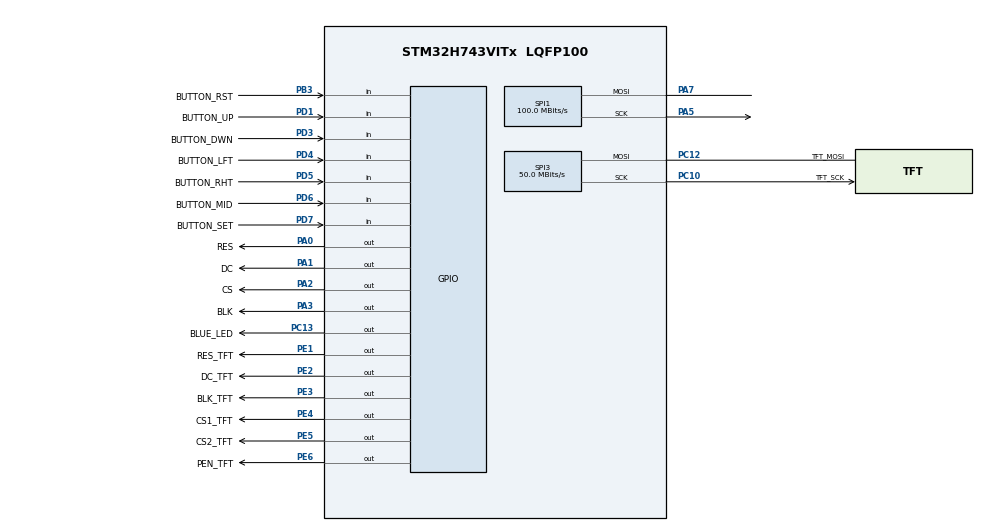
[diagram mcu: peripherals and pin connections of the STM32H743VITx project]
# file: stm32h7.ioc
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CORTEX_M7.CPU_DCache=Disabled
CORTEX_M7.CPU_ICache=Disabled
CORTEX_M7.Enable_S-Cortex_Memory_Protection_Unit_Region11_Settings_S=__NULL
CORTEX_M7.Enable_S-Cortex_Memory_Protection_Unit_Region1_Settings_S=__NULL
CORTEX_M7.default_mode_Activation=0
Dma.Request0=SPI1_TX
Dma.Request1=SPI3_TX
Dma.SPI1_TX.0.Direction=DMA_MEMORY_TO_PERIPH
Dma.SPI1_TX.0.EventEnable=DISABLE
Dma.SPI1_TX.0.FIFOMode=DMA_FIFOMODE_DISABLE
Dma.SPI1_TX.0.Instance=DMA1_Stream0
Dma.SPI1_TX.0.MemDataAlignment=DMA_MDATAALIGN_BYTE
Dma.SPI1_TX.0.MemInc=DMA_MINC_ENABLE
Dma.SPI1_TX.0.Mode=DMA_NORMAL
Dma.SPI1_TX.0.PeriphDataAlignment=DMA_PDATAALIGN_BYTE
Dma.SPI1_TX.0.PeriphInc=DMA_PINC_DISABLE
Dma.SPI1_TX.0.Polarity=HAL_DMAMUX_REQ_GEN_RISING
Dma.SPI1_TX.0.Priority=DMA_PRIORITY_HIGH
Dma.SPI1_TX.0.RequestNumber=1
Dma.SPI1_TX.0.SignalID=NONE
Dma.SPI1_TX.0.SyncEnable=DISABLE
Dma.SPI1_TX.0.SyncPolarity=HAL_DMAMUX_SYNC_NO_EVENT
Dma.SPI1_TX.0.SyncRequestNumber=1
Dma.SPI1_TX.0.SyncSignalID=NONE
Dma.SPI3_TX.1.Direction=DMA_MEMORY_TO_PERIPH
Dma.SPI3_TX.1.EventEnable=DISABLE
Dma.SPI3_TX.1.FIFOMode=DMA_FIFOMODE_ENABLE
Dma.SPI3_TX.1.FIFOThreshold=DMA_FIFO_THRESHOLD_FULL
Dma.SPI3_TX.1.Instance=DMA1_Stream2
Dma.SPI3_TX.1.MemBurst=DMA_MBURST_SINGLE
Dma.SPI3_TX.1.MemDataAlignment=DMA_MDATAALIGN_BYTE
Dma.SPI3_TX.1.MemInc=DMA_MINC_ENABLE
Dma.SPI3_TX.1.Mode=DMA_NORMAL
Dma.SPI3_TX.1.PeriphBurst=DMA_PBURST_SINGLE
Dma.SPI3_TX.1.PeriphDataAlignment=DMA_PDATAALIGN_BYTE
Dma.SPI3_TX.1.PeriphInc=DMA_PINC_DISABLE
Dma.SPI3_TX.1.Polarity=HAL_DMAMUX_REQ_GEN_RISING
Dma.SPI3_TX.1.Priority=DMA_PRIORITY_VERY_HIGH
Dma.SPI3_TX.1.RequestNumber=1
Dma.SPI3_TX.1.SignalID=NONE
Dma.SPI3_TX.1.SyncEnable=DISABLE
Dma.SPI3_TX.1.SyncPolarity=HAL_DMAMUX_SYNC_NO_EVENT
Dma.SPI3_TX.1.SyncRequestNumber=1
Dma.SPI3_TX.1.SyncSignalID=NONE
Mcu.Family=STM32H7
Mcu.Name=STM32H743VITx
Mcu.Package=LQFP100
NVIC.DMA1_Stream0_IRQn=true\:5\:0\:true\:false\:true\:false\:true\:true
NVIC.DMA1_Stream2_IRQn=true\:0\:0\:false\:false\:true\:false\:true\:true
NVIC.PriorityGroup=NVIC_PRIORITYGROUP_4
NVIC.SPI1_IRQn=true\:5\:0\:true\:false\:true\:false\:true\:true
NVIC.SPI3_IRQn=true\:0\:0\:false\:false\:true\:false\:true\:true
NVIC.TIM3_IRQn=true\:0\:0\:false\:false\:true\:true\:true\:true
PA0.GPIO_Label=RES
PA0.GPIO_Speed=GPIO_SPEED_FREQ_VERY_HIGH
PA0.Signal=GPIO_Output
PA1.GPIO_Label=DC
PA1.GPIO_Speed=GPIO_SPEED_FREQ_VERY_HIGH
PA1.Signal=GPIO_Output
PA2.GPIO_Label=CS
PA2.GPIO_Speed=GPIO_SPEED_FREQ_VERY_HIGH
PA2.Signal=GPIO_Output
PA3.GPIO_Label=BLK
PA3.GPIO_Speed=GPIO_SPEED_FREQ_VERY_HIGH
PA3.Signal=GPIO_Output
PA5.GPIO_Speed=GPIO_SPEED_FREQ_VERY_HIGH
PA5.Mode=Simplex_Bidirectional_Master
PA5.Signal=SPI1_SCK
PA7.GPIO_Speed=GPIO_SPEED_FREQ_VERY_HIGH
PA7.Mode=Simplex_Bidirectional_Master
PA7.Signal=SPI1_MOSI
PB3\ (JTDO/TRACESWO).GPIO_Label=BUTTON_RST
PB3\ (JTDO/TRACESWO).Signal=GPIO_Input
PC10.GPIO_Label=TFT_SCK
PC10.GPIO_Speed=GPIO_SPEED_FREQ_VERY_HIGH
PC10.Mode=Simplex_Bidirectional_Master
PC10.Signal=SPI3_SCK
PC11.GPIO_Label=TFT_MISO
PC11.Signal=SPI3_MISO
PC12.GPIO_Label=TFT_MOSI
PC12.GPIO_Speed=GPIO_SPEED_FREQ_VERY_HIGH
PC12.Mode=Simplex_Bidirectional_Master
PC12.Signal=SPI3_MOSI
PC13.GPIO_Label=BLUE_LED
PC13.Signal=GPIO_Output
PD1.GPIO_Label=BUTTON_UP
PD1.GPIO_PuPd=GPIO_PULLUP
PD1.Signal=GPIO_Input
PD3.GPIO_Label=BUTTON_DWN
PD3.GPIO_PuPd=GPIO_PULLUP
PD3.Signal=GPIO_Input
PD4.GPIO_Label=BUTTON_LFT
PD4.GPIO_PuPd=GPIO_PULLUP
PD4.Signal=GPIO_Input
PD5.GPIO_Label=BUTTON_RHT
PD5.GPIO_PuPd=GPIO_PULLUP
PD5.Signal=GPIO_Input
PD6.GPIO_Label=BUTTON_MID
PD6.GPIO_PuPd=GPIO_PULLUP
PD6.Signal=GPIO_Input
PD7.GPIO_Label=BUTTON_SET
PD7.GPIO_PuPd=GPIO_PULLUP
PD7.Signal=GPIO_Input
PE1.GPIO_Label=RES_TFT
PE1.GPIO_Speed=GPIO_SPEED_FREQ_VERY_HIGH
PE1.Signal=GPIO_Output
PE2.GPIO_Label=DC_TFT
PE2.GPIO_Speed=GPIO_SPEED_FREQ_VERY_HIGH
PE2.Signal=GPIO_Output
PE3.GPIO_Label=BLK_TFT
PE3.GPIO_Speed=GPIO_SPEED_FREQ_VERY_HIGH
PE3.Signal=GPIO_Output
PE4.GPIO_Label=CS1_TFT
PE4.GPIO_Speed=GPIO_SPEED_FREQ_VERY_HIGH
PE4.Signal=GPIO_Output
PE5.GPIO_Label=CS2_TFT
PE5.GPIO_Speed=GPIO_SPEED_FREQ_VERY_HIGH
PE5.Signal=GPIO_Output
PE6.GPIO_Label=PEN_TFT
PE6.GPIO_Speed=GPIO_SPEED_FREQ_VERY_HIGH
PE6.Signal=GPIO_Output
PH0-OSC_IN\ (PH0).Mode=HSE-External-Oscillator
PH0-OSC_IN\ (PH0).Signal=RCC_OSC_IN
PH1-OSC_OUT\ (PH1).Mode=HSE-External-Oscillator
PH1-OSC_OUT\ (PH1).Signal=RCC_OSC_OUT
ProjectManager.HeapSize=0x200
ProjectManager.StackSize=0x400
ProjectManager.TargetToolchain=Makefile
RCC.ADCFreq_Value=200000000
RCC.APB1Freq_Value=100000000
RCC.APB2Freq_Value=100000000
RCC.APB3Freq_Value=100000000
RCC.APB4Freq_Value=100000000
RCC.CSICalibrationValue=16
RCC.CortexFreq_Value=400000000
RCC.D1PPRE=RCC_APB3_DIV2
RCC.D2PPRE1=RCC_APB1_DIV2
RCC.D2PPRE2=RCC_APB2_DIV2
RCC.D3PPRE=RCC_APB4_DIV2
RCC.DIVM1=1
RCC.DIVM2=1
RCC.DIVM3=1
RCC.DIVN1=100
RCC.DIVN2=100
RCC.DIVN3=100
RCC.DIVP2=4
RCC.DIVP3=4
RCC.HCLKFreq_Value=200000000
RCC.HPRE=RCC_HCLK_DIV2
RCC.HSE_VALUE=8000000
RCC.PLLFRACN=0
RCC.PLLSourceVirtual=RCC_PLLSOURCE_HSE
RCC.RCC_TIM_PRescaler_Selection=RCC_TIMPRES_ACTIVATED
RCC.SPI123CLockSelection=RCC_SPI123CLKSOURCE_PLL2
RCC.SYSCLKFreq_VALUE=400000000
RCC.SYSCLKSource=RCC_SYSCLKSOURCE_PLLCLK
RCC.USBFreq_Value=400000000
SPI1.BaudRatePrescaler=SPI_BAUDRATEPRESCALER_2
SPI1.CLKPolarity=SPI_POLARITY_LOW
SPI1.CalculateBaudRate=100.0 MBits/s
SPI1.DataSize=SPI_DATASIZE_8BIT
SPI1.Direction=SPI_DIRECTION_1LINE
SPI1.Mode=SPI_MODE_MASTER
SPI1.NSSPMode=SPI_NSS_PULSE_ENABLE
SPI1.VirtualType=VM_MASTER
SPI3.BaudRatePrescaler=SPI_BAUDRATEPRESCALER_4
SPI3.CLKPhase=SPI_PHASE_1EDGE
SPI3.CLKPolarity=SPI_POLARITY_HIGH
SPI3.CalculateBaudRate=50.0 MBits/s
SPI3.DataSize=SPI_DATASIZE_8BIT
SPI3.Direction=SPI_DIRECTION_1LINE
SPI3.Mode=SPI_MODE_MASTER
SPI3.NSSPMode=SPI_NSS_PULSE_DISABLE
SPI3.VirtualType=VM_MASTER
TIM3.AutoReloadPreload=TIM_AUTORELOAD_PRELOAD_ENABLE
TIM3.Period=1000-1
TIM3.Prescaler=200-1
VP_TIM3_VS_ClockSourceINT.Mode=Internal
board=custom

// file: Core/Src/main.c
/* USER CODE BEGIN Header */
/**
  ******************************************************************************
  * @file           : main.c
  * @brief          : Main program body
  ******************************************************************************
  * @attention
  *
  * Copyright (c) 2023 STMicroelectronics.
  * All rights reserved.
  *
  * This software is licensed under terms that can be found in the LICENSE file
  * in the root directory of this software component.
  * If no LICENSE file comes with this software, it is provided AS-IS.
  *
  ******************************************************************************
  */
/* USER CODE END Header */
#include "main.h"
#include "dma.h"
#include "spi.h"
#include "tim.h"
#include "gpio.h"

/* USER CODE BEGIN Includes */
volatile bool spi3_transmit_complete = false;
/* USER CODE END Includes */

void SystemClock_Config(void);
void PeriphCommonClock_Config(void);

int main(void)
{

  /* MCU Configuration--------------------------------------------------------*/

  /* Reset of all peripherals, Initializes the Flash interface and the Systick. */
  HAL_Init();

  /* Configure the system clock */
  SystemClock_Config();

/* Configure the peripherals common clocks */
  PeriphCommonClock_Config();

  /* Initialize all configured peripherals */
  MX_GPIO_Init();
  MX_DMA_Init();
  MX_SPI1_Init();
  MX_SPI3_Init();
  MX_TIM3_Init();
  /* USER CODE BEGIN 2 */
  lv_init();
  lv_port_disp_init();
  // lv_demo_widgets();
  lv_demo_benchmark();
  /* USER CODE END 2 */

  /* Infinite loop */
  /* USER CODE BEGIN WHILE */
  while (1)
  {
    lv_task_handler();
    /* USER CODE END WHILE */

    /* USER CODE BEGIN 3 */
    HAL_Delay(5);
  }
  /* USER CODE END 3 */
}

void SystemClock_Config(void)
{
  RCC_OscInitTypeDef RCC_OscInitStruct = {0};
  RCC_ClkInitTypeDef RCC_ClkInitStruct = {0};

  /** Supply configuration update enable
  */
  HAL_PWREx_ConfigSupply(PWR_LDO_SUPPLY);

  /** Configure the main internal regulator output voltage
  */
  __HAL_PWR_VOLTAGESCALING_CONFIG(PWR_REGULATOR_VOLTAGE_SCALE1);

  while(!__HAL_PWR_GET_FLAG(PWR_FLAG_VOSRDY)) {}

  /** Initializes the RCC Oscillators according to the specified parameters
  * in the RCC_OscInitTypeDef structure.
  */
  RCC_OscInitStruct.OscillatorType = RCC_OSCILLATORTYPE_HSE;
  RCC_OscInitStruct.HSEState = RCC_HSE_ON;
  RCC_OscInitStruct.PLL.PLLState = RCC_PLL_ON;
  RCC_OscInitStruct.PLL.PLLSource = RCC_PLLSOURCE_HSE;
  RCC_OscInitStruct.PLL.PLLM = 1;
  RCC_OscInitStruct.PLL.PLLN = 100;
  RCC_OscInitStruct.PLL.PLLP = 2;
  RCC_OscInitStruct.PLL.PLLQ = 2;
  RCC_OscInitStruct.PLL.PLLR = 2;
  RCC_OscInitStruct.PLL.PLLRGE = RCC_PLL1VCIRANGE_3;
  RCC_OscInitStruct.PLL.PLLVCOSEL = RCC_PLL1VCOWIDE;
  RCC_OscInitStruct.PLL.PLLFRACN = 0;
  if (HAL_RCC_OscConfig(&RCC_OscInitStruct) != HAL_OK)
  {
    Error_Handler();
  }

  /** Initializes the CPU, AHB and APB buses clocks
  */
  RCC_ClkInitStruct.ClockType = RCC_CLOCKTYPE_HCLK|RCC_CLOCKTYPE_SYSCLK
                              |RCC_CLOCKTYPE_PCLK1|RCC_CLOCKTYPE_PCLK2
                              |RCC_CLOCKTYPE_D3PCLK1|RCC_CLOCKTYPE_D1PCLK1;
  RCC_ClkInitStruct.SYSCLKSource = RCC_SYSCLKSOURCE_PLLCLK;
  RCC_ClkInitStruct.SYSCLKDivider = RCC_SYSCLK_DIV1;
  RCC_ClkInitStruct.AHBCLKDivider = RCC_HCLK_DIV2;
  RCC_ClkInitStruct.APB3CLKDivider = RCC_APB3_DIV2;
  RCC_ClkInitStruct.APB1CLKDivider = RCC_APB1_DIV2;
  RCC_ClkInitStruct.APB2CLKDivider = RCC_APB2_DIV2;
  RCC_ClkInitStruct.APB4CLKDivider = RCC_APB4_DIV2;

  if (HAL_RCC_ClockConfig(&RCC_ClkInitStruct, FLASH_LATENCY_2) != HAL_OK)
  {
    Error_Handler();
  }
}

void PeriphCommonClock_Config(void)
{
  RCC_PeriphCLKInitTypeDef PeriphClkInitStruct = {0};

  /** Initializes the peripherals clock
  */
  PeriphClkInitStruct.PeriphClockSelection = RCC_PERIPHCLK_SPI3|RCC_PERIPHCLK_SPI1
                              |RCC_PERIPHCLK_TIM;
  PeriphClkInitStruct.PLL2.PLL2M = 1;
  PeriphClkInitStruct.PLL2.PLL2N = 100;
  PeriphClkInitStruct.PLL2.PLL2P = 4;
  PeriphClkInitStruct.PLL2.PLL2Q = 2;
  PeriphClkInitStruct.PLL2.PLL2R = 2;
  PeriphClkInitStruct.PLL2.PLL2RGE = RCC_PLL2VCIRANGE_3;
  PeriphClkInitStruct.PLL2.PLL2VCOSEL = RCC_PLL2VCOWIDE;
  PeriphClkInitStruct.PLL2.PLL2FRACN = 0;
  PeriphClkInitStruct.Spi123ClockSelection = RCC_SPI123CLKSOURCE_PLL2;
  PeriphClkInitStruct.TIMPresSelection = RCC_TIMPRES_ACTIVATED;

  if (HAL_RCCEx_PeriphCLKConfig(&PeriphClkInitStruct) != HAL_OK)
  {
    Error_Handler();
  }
}

void Error_Handler(void)
{
  __disable_irq();
  while (1)
  {
  }
}
